# STM32L5x2 register map
File version: 1.3
Registers are 32-bit, read-write, reset 0x0 unless marked. A register's access mark holds for its fields unless they carry their own. Offsets are from the block's base; [hi:lo] are bit positions; {n}, {i} and the like mark numbered series.

## PKA
Base 0x420C2000
Same registers: SEC_PKA 0x520C2000
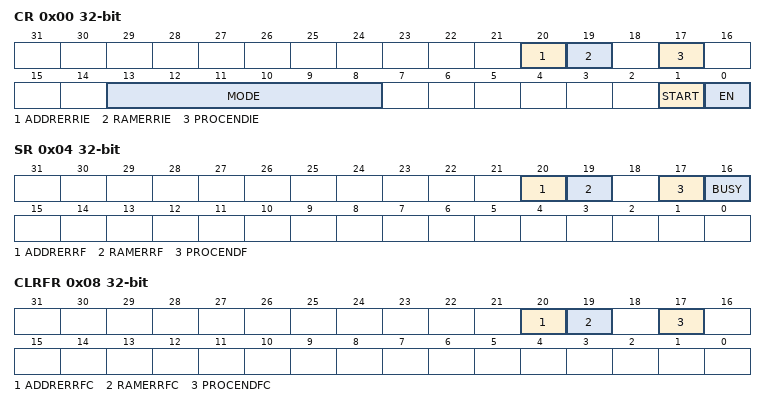
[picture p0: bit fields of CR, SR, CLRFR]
0x00 CR — Control register
  [20] ADDRERRIE — Address error interrupt enable
  [19] RAMERRIE — RAM error interrupt enable
  [17] PROCENDIE — End of operation interrupt enable
  [13:8] MODE — PKA Operation Mode
  [1] START — Start the operation
  [0] EN — Peripheral Enable
0x04 SR ro — PKA status register
  [20] ADDRERRF
  [19] RAMERRF
  [17] PROCENDF — PKA End of Operation flag
  [16] BUSY — PKA operation is in progress
0x08 CLRFR wo — PKA clear flag register
  [20] ADDRERRFC
  [19] RAMERRFC
  [17] PROCENDFC — Clear PKA End of Operation flag

## DBGMCU — MCU debug component
Base 0xE0044000
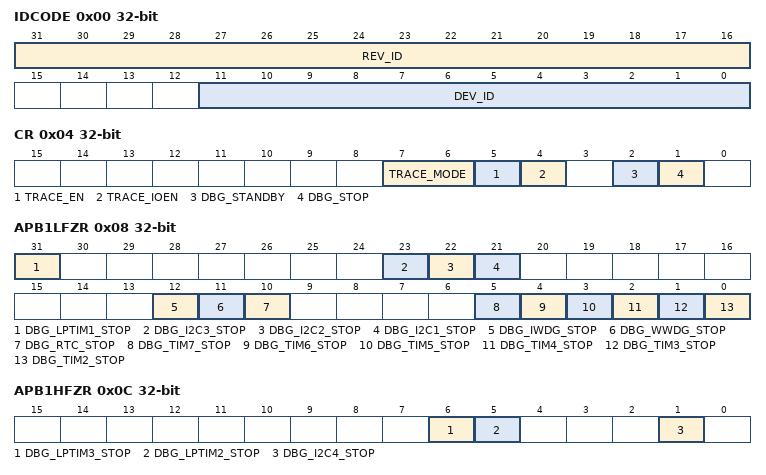
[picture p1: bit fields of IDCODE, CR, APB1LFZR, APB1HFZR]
0x00 IDCODE ro — DBGMCU_IDCODE
  [31:16] REV_ID — Revision identifie
  [11:0] DEV_ID — Device identifier
0x04 CR — Debug MCU configuration register
  [7:6] TRACE_MODE — Trace pin assignment control
  [5] TRACE_EN — trace port and clock enable
  [4] TRACE_IOEN — Trace pin assignment control
  [2] DBG_STANDBY — Debug Standby mode
  [1] DBG_STOP — Debug Stop mode
0x08 APB1LFZR — Debug MCU APB1 freeze register1
  [31] DBG_LPTIM1_STOP — LPTIM1 counter stopped when core is halted
  [23] DBG_I2C3_STOP — I2C3 SMBUS timeout counter stopped when core is halted
  [22] DBG_I2C2_STOP — I2C2 SMBUS timeout counter stopped when core is halted
  [21] DBG_I2C1_STOP — I2C1 SMBUS timeout counter stopped when core is halted
  [12] DBG_IWDG_STOP — Independent watchdog counter stopped when core is halted
  [11] DBG_WWDG_STOP — Window watchdog counter stopped when core is halted
  [10] DBG_RTC_STOP — RTC counter stopped when core is halted
  [5] DBG_TIM7_STOP — TIM7 counter stopped when core is halted
  [4] DBG_TIM6_STOP — TIM6 counter stopped when core is halted
  [3] DBG_TIM5_STOP — TIM5 stop in debug
  [2] DBG_TIM4_STOP — TIM4 stop in debug
  [1] DBG_TIM3_STOP — TIM3 stop in debug
  [0] DBG_TIM2_STOP — TIM2 counter stopped when core is halted
0x0C APB1HFZR — Debug MCU APB1 freeze register 2
  [6] DBG_LPTIM3_STOP — LPTIM3 stop in debug
  [5] DBG_LPTIM2_STOP — LPTIM2 counter stopped when core is halted
  [1] DBG_I2C4_STOP — I2C4 stop in debug
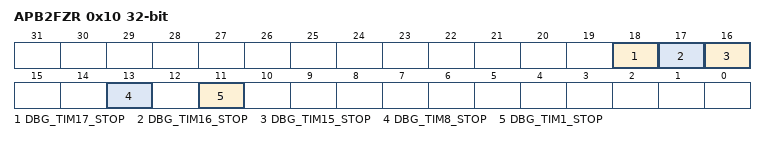
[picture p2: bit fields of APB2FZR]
0x10 APB2FZR — Debug MCU APB2 freeze register
  [18] DBG_TIM17_STOP
  [17] DBG_TIM16_STOP — TIM16 counter stopped when core is halted
  [16] DBG_TIM15_STOP — TIM15 counter stopped when core is halted
  [13] DBG_TIM8_STOP — TIM8 stop in debug
  [11] DBG_TIM1_STOP — TIM1 counter stopped when core is halted

## USB — Universal serial bus full-speed device interface
Base 0x4000D400
Same registers: SEC_USB 0x5000D400
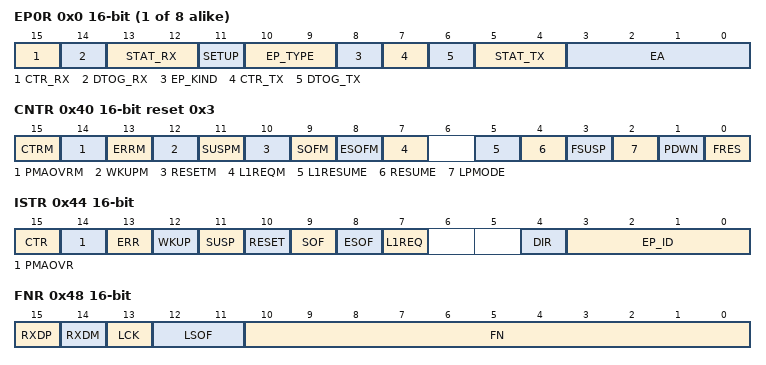
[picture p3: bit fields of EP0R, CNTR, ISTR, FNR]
{0x0+4i} EP{i}R 16-bit (i=0..7) — endpoint {i} register
  [15] CTR_RX — Correct transfer for reception
  [14] DTOG_RX — Data Toggle, for reception transfers
  [13:12] STAT_RX — Status bits, for reception transfers
  [11] SETUP — Setup transaction completed
  [10:9] EP_TYPE — Endpoint type
  [8] EP_KIND — Endpoint kind
  [7] CTR_TX — Correct Transfer for transmission
  [6] DTOG_TX — Data Toggle, for transmission transfers
  [5:4] STAT_TX — Status bits, for transmission transfers
  [3:0] EA — Endpoint address
0x40 CNTR 16-bit reset 0x3 — control register
  [15] CTRM — Correct transfer interrupt mask
  [14] PMAOVRM — Packet memory area over / underrun interrupt mask
  [13] ERRM — Error interrupt mask
  [12] WKUPM — Wakeup interrupt mask
  [11] SUSPM — Suspend mode interrupt mask
  [10] RESETM — USB reset interrupt mask
  [9] SOFM — Start of frame interrupt mask
  [8] ESOFM — Expected start of frame interrupt mask
  [7] L1REQM — LPM L1 state request interrupt mask
  [5] L1RESUME — LPM L1 Resume request
  [4] RESUME — Resume request
  [3] FSUSP — Force suspend
  [2] LPMODE — Low-power mode
  [1] PDWN — Power down
  [0] FRES — Force USB Reset
0x44 ISTR 16-bit access per field — interrupt status register
  [15] CTR ro — Correct transfer
  [14] PMAOVR rw — Packet memory area over / underrun
  [13] ERR rw — Error
  [12] WKUP rw — Wakeup
  [11] SUSP rw — Suspend mode request
  [10] RESET rw — reset request
  [9] SOF rw — start of frame
  [8] ESOF rw — Expected start frame
  [7] L1REQ rw — LPM L1 state request
  [4] DIR ro — Direction of transaction
  [3:0] EP_ID ro — Endpoint Identifier
0x48 FNR 16-bit ro — frame number register
  [15] RXDP — Receive data + line status
  [14] RXDM — Receive data - line status
  [13] LCK — Locked
  [12:11] LSOF — Lost SOF
  [10:0] FN — Frame number
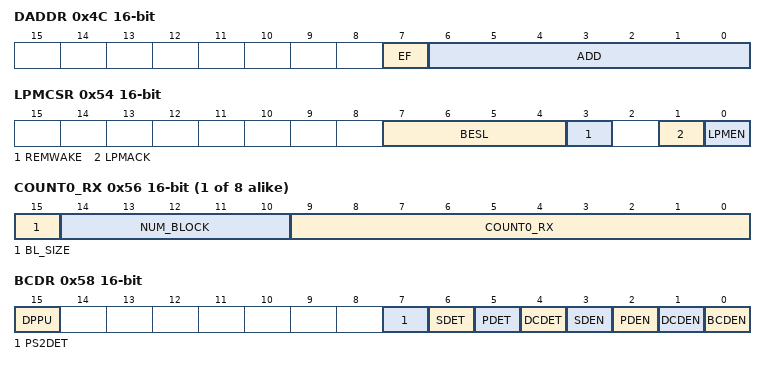
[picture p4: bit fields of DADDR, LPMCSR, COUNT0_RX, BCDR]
0x4C DADDR 16-bit — device address
  [7] EF — Enable function
  [6:0] ADD — Device address
0x50 BTABLE 16-bit — Buffer table address
  [15:3] BTABLE — Buffer table
{0x52+8i} COUNT{i}_TX 16-bit (i=0..7) — Transmission byte count 0
  [9:0] COUNT{i}_TX — Transmission byte count
0x54 LPMCSR 16-bit — LPM control and status register
  [7:4] BESL — BESL value
  [3] REMWAKE — RemoteWake value
  [1] LPMACK — LPM Token acknowledge enable
  [0] LPMEN — LPM support enable
{0x56+8i} COUNT{i}_RX 16-bit access per field (i=0..7) — Reception byte count 0
  [15] BL_SIZE rw — Block size
  [14:10] NUM_BLOCK rw — Number of blocks
  [9:0] COUNT{i}_RX ro — Reception byte count
0x58 BCDR 16-bit — Battery charging detector
  [15] DPPU — DP pull-up control
  [7] PS2DET — DM pull-up detection status
  [6] SDET — Secondary detection (SD) status
  [5] PDET — Primary detection (PD) status
  [4] DCDET — Data contact detection (DCD) status
  [3] SDEN — Secondary detection (SD) mode enable
  [2] PDEN — Primary detection (PD) mode enable
  [1] DCDEN — Data contact detection (DCD) mode enable
  [0] BCDEN — Battery charging detector (BCD) enable
{0x5C+8i} ADDR{i}_RX 16-bit (i=0..7) — Reception buffer address 0
  [15:1] ADDR{i}_RX — Reception buffer address
